# RESOLVER_RESOLVER_REGS_502CB000h register map
Vendor: Texas Instruments
Registers are 32-bit, read-write, reset 0x0 unless marked. A register's access mark holds for its fields unless they carry their own. Offsets are as the file gives them; [hi:lo] are bit positions; {n}, {i} and the like mark numbered series; 'fields as' and 'values as' point back to an identical list.

## RESOLVER_REGS (part 2 of 2)
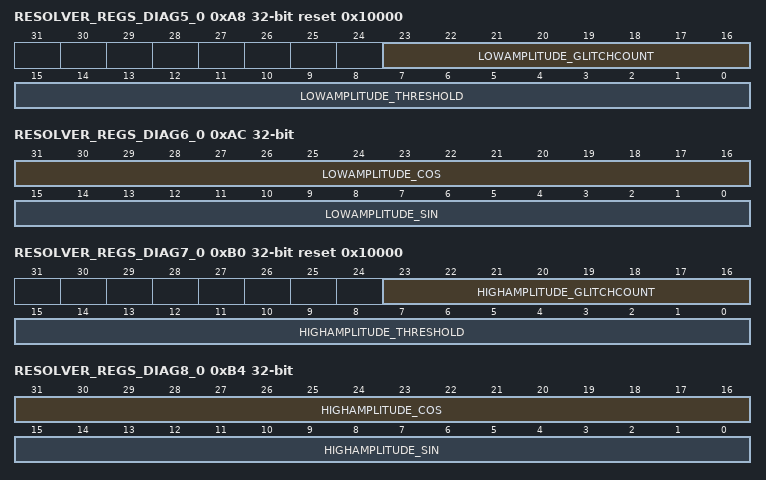
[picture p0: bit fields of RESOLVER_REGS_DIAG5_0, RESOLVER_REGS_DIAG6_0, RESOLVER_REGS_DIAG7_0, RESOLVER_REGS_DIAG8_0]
0xA8 RESOLVER_REGS_DIAG5_0 reset 0x10000 — Diag5 0
  [23:16] LOWAMPLITUDE_GLITCHCOUNT — Counter limit, how many times before issuing error
  [15:0] LOWAMPLITUDE_THRESHOLD — Hi threshold to detect lowamplitude. Both sin and cos need to be lower than this at the same time
0xAC RESOLVER_REGS_DIAG6_0 ro — Diag6 0
  [31:16] LOWAMPLITUDE_COS — Value of cos channel at the error trigger instant
  [15:0] LOWAMPLITUDE_SIN — Value of sin channel at the error trigger instant
0xB0 RESOLVER_REGS_DIAG7_0 reset 0x10000 — Diag7 0
  [23:16] HIGHAMPLITUDE_GLITCHCOUNT — Counter limit, how many times before issuing error
  [15:0] HIGHAMPLITUDE_THRESHOLD — Hi threshold to detect highamplitude. Both sin and cos need to be higher than this at the same time
0xB4 RESOLVER_REGS_DIAG8_0 ro — Diag8 0
  [31:16] HIGHAMPLITUDE_COS — Value of cos channel at the error trigger instant
  [15:0] HIGHAMPLITUDE_SIN — Value of sin channel at the error trigger instant
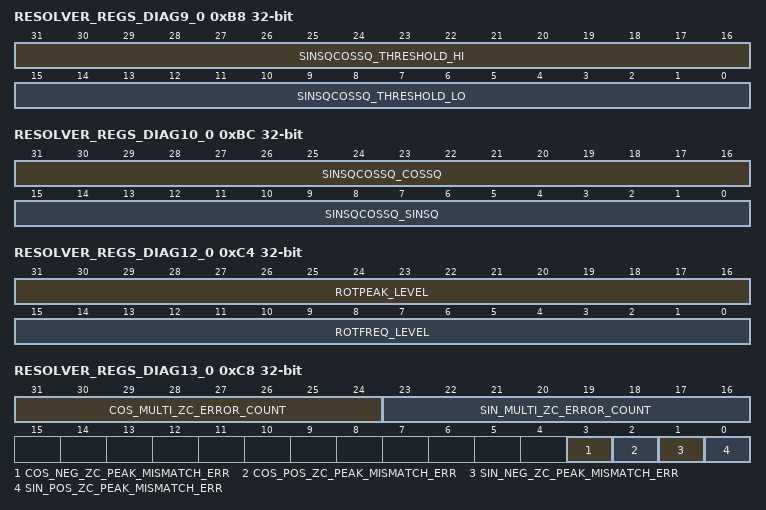
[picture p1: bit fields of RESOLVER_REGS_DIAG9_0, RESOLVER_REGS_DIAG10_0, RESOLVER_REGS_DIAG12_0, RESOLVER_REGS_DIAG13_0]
0xB8 RESOLVER_REGS_DIAG9_0 — Diag9 0
  [31:16] SINSQCOSSQ_THRESHOLD_HI — High threshold to detect sinsqcossq. Sin^2+Cos^2 s needs to be lower than this
  [15:0] SINSQCOSSQ_THRESHOLD_LO — Low threshold to detect sinsqcossq. Sin^2+Cos^2 s needs to be lower than this
0xBC RESOLVER_REGS_DIAG10_0 ro — Diag10 0
  [31:16] SINSQCOSSQ_COSSQ — Actual cossq value on error trigger ether lo or hi triggered, first event
  [15:0] SINSQCOSSQ_SINSQ — Actual sinsq value on error trigger ether lo or hi triggered, first event
0xC0 RESOLVER_REGS_DIAG11_0 reset 0x1 — Diag11 0
  [7:0] SINSQCOSSQ_GLITCHCOUNT — Counter limit, how many times before issuing error
0xC4 RESOLVER_REGS_DIAG12_0 — Diag12 0
  [31:16] ROTPEAK_LEVEL — Peak level of rotational sin/cos when other signal is zero crossing
  [15:0] ROTFREQ_LEVEL — Zero crossing detection level of rotational sin/cos
0xC8 RESOLVER_REGS_DIAG13_0 ro — Diag13 0
  [31:24] COS_MULTI_ZC_ERROR_COUNT — Status of cos Capture number of faulty zcs
  [23:16] SIN_MULTI_ZC_ERROR_COUNT — Status of sin Capture number of faulty zcs
  [3] COS_NEG_ZC_PEAK_MISMATCH_ERR — During negative cos zero-crossing cos is not + or - peak
  [2] COS_POS_ZC_PEAK_MISMATCH_ERR — During positive cos zero-croscosg cos is not + or - peak
  [1] SIN_NEG_ZC_PEAK_MISMATCH_ERR — During negative sin zero-crossing cos is not + or - peak
  [0] SIN_POS_ZC_PEAK_MISMATCH_ERR — During positive sin zero-crossing cos is not + or - peak
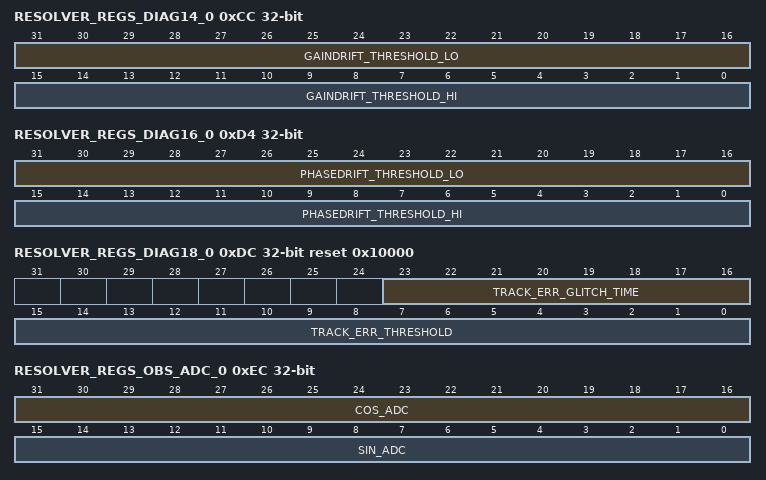
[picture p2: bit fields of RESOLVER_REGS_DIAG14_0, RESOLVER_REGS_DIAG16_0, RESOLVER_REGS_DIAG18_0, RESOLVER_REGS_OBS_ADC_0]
0xCC RESOLVER_REGS_DIAG14_0 — Diag14 0
  [31:16] GAINDRIFT_THRESHOLD_LO — Lo threshold to detect cos_gain drift
  [15:0] GAINDRIFT_THRESHOLD_HI — Hi threshold to detect cos_gain drift
0xD0 RESOLVER_REGS_DIAG15_0 reset 0x1 — Diag15 0
  [7:0] GAINDRIFT_GLITCHCOUNT — Counter limit, how many times before issuing error
0xD4 RESOLVER_REGS_DIAG16_0 — Diag16 0
  [31:16] PHASEDRIFT_THRESHOLD_LO — Lo threshold to detect cos phase drift
  [15:0] PHASEDRIFT_THRESHOLD_HI — Hi threshold to detect cos phase drift
0xD8 RESOLVER_REGS_DIAG17_0 reset 0x1 — Diag17 0
  [7:0] PHASEDRIFT_GLITCHCOUNT — Counter limit, how many times before issuing error
0xDC RESOLVER_REGS_DIAG18_0 reset 0x10000 — Diag18 0
  [23:16] TRACK_ERR_GLITCH_TIME — NOT USED
  [15:0] TRACK_ERR_THRESHOLD — Tracking error treshold
0xEC RESOLVER_REGS_OBS_ADC_0 ro — Sw Obs adc data post latch and avg if enabled
  [31:16] COS_ADC — Signed SW Obs adc data post latch and avg if enabled
  [15:0] SIN_ADC — Signed SW Obs adc data post latch and avg if enabled
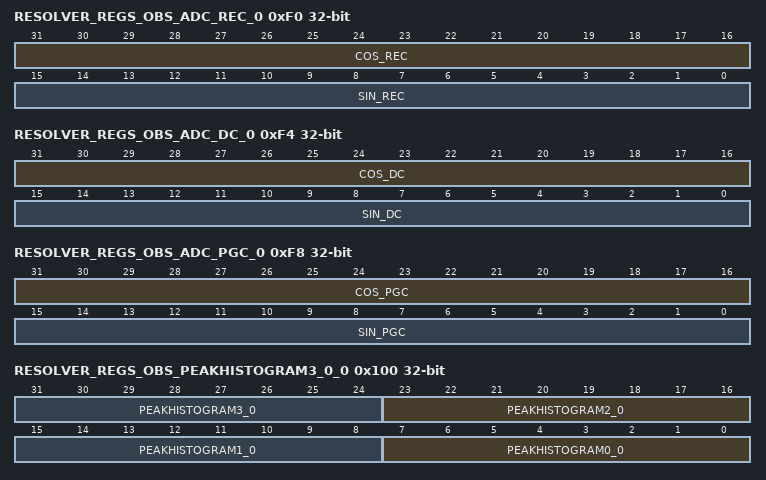
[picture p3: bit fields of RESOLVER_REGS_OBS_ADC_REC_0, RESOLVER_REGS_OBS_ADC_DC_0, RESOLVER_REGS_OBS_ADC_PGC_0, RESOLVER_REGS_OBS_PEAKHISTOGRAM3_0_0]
0xF0 RESOLVER_REGS_OBS_ADC_REC_0 ro — Sw Obs adc data post recovered data, so post dec
  [31:16] COS_REC — Signed SW Ob sadc data post recovered data, so post dec
  [15:0] SIN_REC — Signed SW Obs adc data post recovered data, so post dec
0xF4 RESOLVER_REGS_OBS_ADC_DC_0 ro — Sw Obs adc data post dc offset.
  [31:16] COS_DC — Signed SW Obs adc data post dc offset
  [15:0] SIN_DC — Signed SW Obs adc data post dc offset
0xF8 RESOLVER_REGS_OBS_ADC_PGC_0 ro — Sw Obs post phase and gain correction .
  [31:16] COS_PGC — Signed SW Obs adc data post phase and gain correction
  [15:0] SIN_PGC — Signed SW Obs adc data post phase and gain correction
0x100 RESOLVER_REGS_OBS_PEAKHISTOGRAM3_0_0 ro — SW obs peak histogram buckets.
  [8n+7:8n] PEAKHISTOGRAM{n}_0 (n=0..3) — Ideal sample bucket{n}
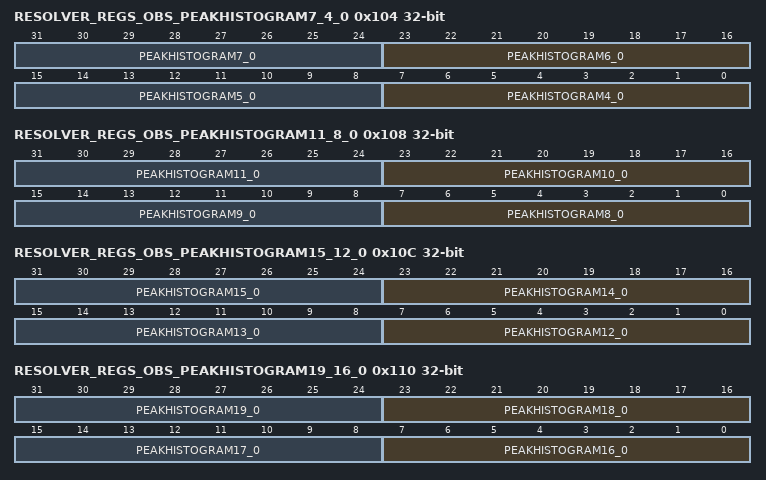
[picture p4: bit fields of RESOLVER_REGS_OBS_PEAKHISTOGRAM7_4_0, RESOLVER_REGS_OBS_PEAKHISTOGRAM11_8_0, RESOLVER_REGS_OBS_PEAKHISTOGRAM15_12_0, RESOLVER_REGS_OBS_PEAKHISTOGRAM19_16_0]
0x104 RESOLVER_REGS_OBS_PEAKHISTOGRAM7_4_0 ro — SW obs peak histogram buckets .
  [8n-25:8n-32] PEAKHISTOGRAM{n}_0 (n=4..7) — Ideal sample bucket{n}
0x108 RESOLVER_REGS_OBS_PEAKHISTOGRAM11_8_0 ro — SW obs peak histogram buckets .
  [8n-57:8n-64] PEAKHISTOGRAM{n}_0 (n=8..11) — Ideal sample bucket{n}
0x10C RESOLVER_REGS_OBS_PEAKHISTOGRAM15_12_0 ro — SW obs peak histogram buckets .
  [8n-89:8n-96] PEAKHISTOGRAM{n}_0 (n=12..15) — Ideal sample bucket{n}
0x110 RESOLVER_REGS_OBS_PEAKHISTOGRAM19_16_0 ro — SW obs peak histogram buckets .
  [8n-121:8n-128] PEAKHISTOGRAM{n}_0 (n=16..19) — Ideal sample bucket{n}
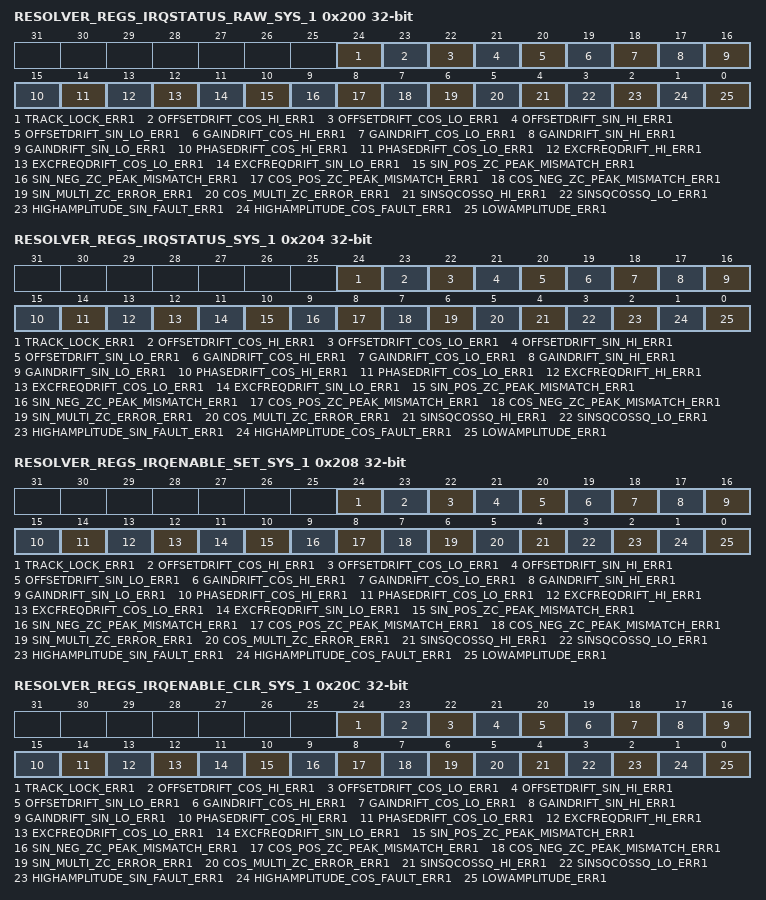
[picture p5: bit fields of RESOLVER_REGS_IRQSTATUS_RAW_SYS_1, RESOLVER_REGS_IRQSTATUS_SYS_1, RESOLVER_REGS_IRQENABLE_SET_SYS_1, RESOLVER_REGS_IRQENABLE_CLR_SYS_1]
0x200 RESOLVER_REGS_IRQSTATUS_RAW_SYS_1 access not given — Interrupt Raw Status Register for Core1.
  [24] TRACK_LOCK_ERR1 — Raw status of error interrupt for track_lock_err Write 1 to set the (raw) status, mostly for debug. Writing a 0 has no effect. (access R/W1TS)
  [23] OFFSETDRIFT_COS_HI_ERR1 — Raw status of error interrupt for offsetdrift_cos_hi_err Write 1 to set the (raw) status, mostly for debug. Writing a 0 has no effect. (access R/W1TS)
  [22] OFFSETDRIFT_COS_LO_ERR1 — Raw status of error interrupt for offsetdrift_cos_lo_err Write 1 to set the (raw) status, mostly for debug. Writing a 0 has no effect. (access R/W1TS)
  [21] OFFSETDRIFT_SIN_HI_ERR1 — Raw status of error interrupt for offsetdrift_sin_hi_err Write 1 to set the (raw) status, mostly for debug. Writing a 0 has no effect. (access R/W1TS)
  [20] OFFSETDRIFT_SIN_LO_ERR1 — Raw status of error interrupt for offsetdrift_sin_lo_err Write 1 to set the (raw) status, mostly for debug. Writing a 0 has no effect. (access R/W1TS)
  [19] GAINDRIFT_COS_HI_ERR1 — Raw status of error interrupt for gaindrift_cos_hi_err Write 1 to set the (raw) status, mostly for debug. Writing a 0 has no effect. (access R/W1TS)
  [18] GAINDRIFT_COS_LO_ERR1 — Raw status of error interrupt for gaindrift_cos_lo_err Write 1 to set the (raw) status, mostly for debug. Writing a 0 has no effect. (access R/W1TS)
  [17] GAINDRIFT_SIN_HI_ERR1 — Raw status of error interrupt for gaindrift_sin_hi_err Write 1 to set the (raw) status, mostly for debug. Writing a 0 has no effect. (access R/W1TS)
  [16] GAINDRIFT_SIN_LO_ERR1 — Raw status of error interrupt for gaindrift_sin_lo_err Write 1 to set the (raw) status, mostly for debug. Writing a 0 has no effect. (access R/W1TS)
  [15] PHASEDRIFT_COS_HI_ERR1 — Raw status of error interrupt for phasedrift_cos_hi_err Write 1 to set the (raw) status, mostly for debug. Writing a 0 has no effect. (access R/W1TS)
  [14] PHASEDRIFT_COS_LO_ERR1 — Raw status of error interrupt for phasedrift_cos_lo_err Write 1 to set the (raw) status, mostly for debug. Writing a 0 has no effect. (access R/W1TS)
  [13] EXCFREQDRIFT_HI_ERR1 — Raw status of error interrupt for excfreqdrift_hi_err Write 1 to set the (raw) status, mostly for debug. Writing a 0 has no effect. (access R/W1TS)
  [12] EXCFREQDRIFT_COS_LO_ERR1 — Raw status of error interrupt for excfreqdrift_cos_lo_err Write 1 to set the (raw) status, mostly for debug. Writing a 0 has no effect. (access R/W1TS)
  [11] EXCFREQDRIFT_SIN_LO_ERR1 — Raw status of error interrupt for excfreqdrift_sin_lo_err Write 1 to set the (raw) status, mostly for debug. Writing a 0 has no effect. (access R/W1TS)
  [10] SIN_POS_ZC_PEAK_MISMATCH_ERR1 — Raw status of error interrupt for sin_pos_zc_peak_mismatch_err Write 1 to set the (raw) status, mostly for debug. Writing a 0 has no effect. (access R/W1TS)
  [9] SIN_NEG_ZC_PEAK_MISMATCH_ERR1 — Raw status of error interrupt for sin_neg_zc_peak_mismatch_err Write 1 to set the (raw) status, mostly for debug. Writing a 0 has no effect. (access R/W1TS)
  [8] COS_POS_ZC_PEAK_MISMATCH_ERR1 — Raw status of error interrupt for cos_pos_zc_peak_mismatch_err Write 1 to set the (raw) status, mostly for debug. Writing a 0 has no effect. (access R/W1TS)
  [7] COS_NEG_ZC_PEAK_MISMATCH_ERR1 — Raw status of error interrupt for cos_neg_zc_peak_mismatch_err Write 1 to set the (raw) status, mostly for debug. Writing a 0 has no effect. (access R/W1TS)
  [6] SIN_MULTI_ZC_ERROR_ERR1 — Raw status of error interrupt for sin_multi_zc_error_err Write 1 to set the (raw) status, mostly for debug. Writing a 0 has no effect. (access R/W1TS)
  [5] COS_MULTI_ZC_ERROR_ERR1 — Raw status of error interrupt for cos_multi_zc_error_err Write 1 to set the (raw) status, mostly for debug. Writing a 0 has no effect. (access R/W1TS)
  [4] SINSQCOSSQ_HI_ERR1 — Raw status of error interrupt for sinsqcossq_hi_err Write 1 to set the (raw) status, mostly for debug. Writing a 0 has no effect. (access R/W1TS)
  [3] SINSQCOSSQ_LO_ERR1 — Raw status of error interrupt for sinsqcossq_lo_err Write 1 to set the (raw) status, mostly for debug. Writing a 0 has no effect. (access R/W1TS)
  [2] HIGHAMPLITUDE_SIN_FAULT_ERR1 — Raw status of error interrupt for highamplitude_sin_fault_err Write 1 to set the (raw) status, mostly for debug. Writing a 0 has no effect. (access R/W1TS)
  [1] HIGHAMPLITUDE_COS_FAULT_ERR1 — Raw status of error interrupt for highamplitude_cos_fault_err Write 1 to set the (raw) status, mostly for debug. Writing a 0 has no effect. (access R/W1TS)
  [0] LOWAMPLITUDE_ERR1 — Raw status of error interrupt for lowamplitude_err Write 1 to set the (raw) status, mostly for debug. Writing a 0 has no effect. (access R/W1TS)
0x204 RESOLVER_REGS_IRQSTATUS_SYS_1 access not given — Interrupt Status Register for Core1.
  [24] TRACK_LOCK_ERR1 — Enabled status of error interrupt for track_lock_err Write 1 to clear the status after interrupt has been serviced (raw status gets cleared, i.e. even if not enabled). Writing a 0 has no effect. (access R/W1TC)
  [23] OFFSETDRIFT_COS_HI_ERR1 — Enabled status of error interrupt for offsetdrift_cos_hi_err Write 1 to clear the status after interrupt has been serviced (raw status gets cleared, i.e. even if not enabled). Writing a 0 has no effect. (access R/W1TC)
  [22] OFFSETDRIFT_COS_LO_ERR1 — Enabled status of error interrupt for offsetdrift_cos_lo_err Write 1 to clear the status after interrupt has been serviced (raw status gets cleared, i.e. even if not enabled). Writing a 0 has no effect. (access R/W1TC)
  [21] OFFSETDRIFT_SIN_HI_ERR1 — Enabled status of error interrupt for offsetdrift_sin_hi_err Write 1 to clear the status after interrupt has been serviced (raw status gets cleared, i.e. even if not enabled). Writing a 0 has no effect. (access R/W1TC)
  [20] OFFSETDRIFT_SIN_LO_ERR1 — Enabled status of error interrupt for offsetdrift_sin_lo_err Write 1 to clear the status after interrupt has been serviced (raw status gets cleared, i.e. even if not enabled). Writing a 0 has no effect. (access R/W1TC)
  [19] GAINDRIFT_COS_HI_ERR1 — Enabled status of error interrupt for gaindrift_cos_hi_err Write 1 to clear the status after interrupt has been serviced (raw status gets cleared, i.e. even if not enabled). Writing a 0 has no effect. (access R/W1TC)
  [18] GAINDRIFT_COS_LO_ERR1 — Enabled status of error interrupt for gaindrift_cos_lo_err Write 1 to clear the status after interrupt has been serviced (raw status gets cleared, i.e. even if not enabled). Writing a 0 has no effect. (access R/W1TC)
  [17] GAINDRIFT_SIN_HI_ERR1 — Enabled status of error interrupt for gaindrift_sin_hi_err Write 1 to clear the status after interrupt has been serviced (raw status gets cleared, i.e. even if not enabled). Writing a 0 has no effect. (access R/W1TC)
  [16] GAINDRIFT_SIN_LO_ERR1 — Enabled status of error interrupt for gaindrift_sin_lo_err Write 1 to clear the status after interrupt has been serviced (raw status gets cleared, i.e. even if not enabled). Writing a 0 has no effect. (access R/W1TC)
  [15] PHASEDRIFT_COS_HI_ERR1 — Enabled status of error interrupt for phasedrift_cos_hi_err Write 1 to clear the status after interrupt has been serviced (raw status gets cleared, i.e. even if not enabled). Writing a 0 has no effect. (access R/W1TC)
  [14] PHASEDRIFT_COS_LO_ERR1 — Enabled status of error interrupt for phasedrift_cos_lo_err Write 1 to clear the status after interrupt has been serviced (raw status gets cleared, i.e. even if not enabled). Writing a 0 has no effect. (access R/W1TC)
  [13] EXCFREQDRIFT_HI_ERR1 — Enabled status of error interrupt for excfreqdrift_hi_err Write 1 to clear the status after interrupt has been serviced (raw status gets cleared, i.e. even if not enabled). Writing a 0 has no effect. (access R/W1TC)
  [12] EXCFREQDRIFT_COS_LO_ERR1 — Enabled status of error interrupt for excfreqdrift_cos_lo_err Write 1 to clear the status after interrupt has been serviced (raw status gets cleared, i.e. even if not enabled). Writing a 0 has no effect. (access R/W1TC)
  [11] EXCFREQDRIFT_SIN_LO_ERR1 — Enabled status of error interrupt for excfreqdrift_sin_lo_err Write 1 to clear the status after interrupt has been serviced (raw status gets cleared, i.e. even if not enabled). Writing a 0 has no effect. (access R/W1TC)
  [10] SIN_POS_ZC_PEAK_MISMATCH_ERR1 — Enabled status of error interrupt for sin_pos_zc_peak_mismatch_err Write 1 to clear the status after interrupt has been serviced (raw status gets cleared, i.e. even if not enabled). Writing a 0 has no effect. (access R/W1TC)
  [9] SIN_NEG_ZC_PEAK_MISMATCH_ERR1 — Enabled status of error interrupt for sin_neg_zc_peak_mismatch_err Write 1 to clear the status after interrupt has been serviced (raw status gets cleared, i.e. even if not enabled). Writing a 0 has no effect. (access R/W1TC)
  [8] COS_POS_ZC_PEAK_MISMATCH_ERR1 — Enabled status of error interrupt for cos_pos_zc_peak_mismatch_err Write 1 to clear the status after interrupt has been serviced (raw status gets cleared, i.e. even if not enabled). Writing a 0 has no effect. (access R/W1TC)
  [7] COS_NEG_ZC_PEAK_MISMATCH_ERR1 — Enabled status of error interrupt for cos_neg_zc_peak_mismatch_err Write 1 to clear the status after interrupt has been serviced (raw status gets cleared, i.e. even if not enabled). Writing a 0 has no effect. (access R/W1TC)
  [6] SIN_MULTI_ZC_ERROR_ERR1 — Enabled status of error interrupt for sin_multi_zc_error_err Write 1 to clear the status after interrupt has been serviced (raw status gets cleared, i.e. even if not enabled). Writing a 0 has no effect. (access R/W1TC)
  [5] COS_MULTI_ZC_ERROR_ERR1 — Enabled status of error interrupt for cos_multi_zc_error_err Write 1 to clear the status after interrupt has been serviced (raw status gets cleared, i.e. even if not enabled). Writing a 0 has no effect. (access R/W1TC)
  [4] SINSQCOSSQ_HI_ERR1 — Enabled status of error interrupt for sinsqcossq_hi_err Write 1 to clear the status after interrupt has been serviced (raw status gets cleared, i.e. even if not enabled). Writing a 0 has no effect. (access R/W1TC)
  [3] SINSQCOSSQ_LO_ERR1 — Enabled status of error interrupt for sinsqcossq_lo_err Write 1 to clear the status after interrupt has been serviced (raw status gets cleared, i.e. even if not enabled). Writing a 0 has no effect. (access R/W1TC)
  [2] HIGHAMPLITUDE_SIN_FAULT_ERR1 — Enabled status of error interrupt for highamplitude_sin_fault_err Write 1 to clear the status after interrupt has been serviced (raw status gets cleared, i.e. even if not enabled). Writing a 0 has no effect. (access R/W1TC)
  [1] HIGHAMPLITUDE_COS_FAULT_ERR1 — Enabled status of error interrupt for highamplitude_cos_fault_err Write 1 to clear the status after interrupt has been serviced (raw status gets cleared, i.e. even if not enabled). Writing a 0 has no effect. (access R/W1TC)
  [0] LOWAMPLITUDE_ERR1 — Enabled status of error interrupt for lowamplitude_err Write 1 to clear the status after interrupt has been serviced (raw status gets cleared, i.e. even if not enabled). Writing a 0 has no effect. (access R/W1TC)
0x208 RESOLVER_REGS_IRQENABLE_SET_SYS_1 access not given — Interrupt Enable Set Register for Core1.
  [24] TRACK_LOCK_ERR1 — Enable set for track_lock_err . Writing a 1 will enable the interrupt, and set this bit as well as the corresponding Interrupt Enable Clear Register. Writing a 0 has no effect. (access R/W1TS)
  [23] OFFSETDRIFT_COS_HI_ERR1 — Enable set for offsetdrift_cos_hi_err . Writing a 1 will enable the interrupt, and set this bit as well as the corresponding Interrupt Enable Clear Register. Writing a 0 has no effect. (access R/W1TS)
  [22] OFFSETDRIFT_COS_LO_ERR1 — Enable set for offsetdrift_cos_lo_err . Writing a 1 will enable the interrupt, and set this bit as well as the corresponding Interrupt Enable Clear Register. Writing a 0 has no effect. (access R/W1TS)
  [21] OFFSETDRIFT_SIN_HI_ERR1 — Enable set for offsetdrift_sin_hi_err . Writing a 1 will enable the interrupt, and set this bit as well as the corresponding Interrupt Enable Clear Register. Writing a 0 has no effect. (access R/W1TS)
  [20] OFFSETDRIFT_SIN_LO_ERR1 — Enable set for offsetdrift_sin_lo_err . Writing a 1 will enable the interrupt, and set this bit as well as the corresponding Interrupt Enable Clear Register. Writing a 0 has no effect. (access R/W1TS)
  [19] GAINDRIFT_COS_HI_ERR1 — Enable set for gaindrift_cos_hi_err . Writing a 1 will enable the interrupt, and set this bit as well as the corresponding Interrupt Enable Clear Register. Writing a 0 has no effect. (access R/W1TS)
  [18] GAINDRIFT_COS_LO_ERR1 — Enable set for gaindrift_cos_lo_err . Writing a 1 will enable the interrupt, and set this bit as well as the corresponding Interrupt Enable Clear Register. Writing a 0 has no effect. (access R/W1TS)
  [17] GAINDRIFT_SIN_HI_ERR1 — Enable set for gaindrift_sin_hi_err . Writing a 1 will enable the interrupt, and set this bit as well as the corresponding Interrupt Enable Clear Register. Writing a 0 has no effect. (access R/W1TS)
  [16] GAINDRIFT_SIN_LO_ERR1 — Enable set for gaindrift_sin_lo_err . Writing a 1 will enable the interrupt, and set this bit as well as the corresponding Interrupt Enable Clear Register. Writing a 0 has no effect. (access R/W1TS)
  [15] PHASEDRIFT_COS_HI_ERR1 — Enable set for phasedrift_cos_hi_err . Writing a 1 will enable the interrupt, and set this bit as well as the corresponding Interrupt Enable Clear Register. Writing a 0 has no effect. (access R/W1TS)
  [14] PHASEDRIFT_COS_LO_ERR1 — Enable set for phasedrift_cos_lo_err . Writing a 1 will enable the interrupt, and set this bit as well as the corresponding Interrupt Enable Clear Register. Writing a 0 has no effect. (access R/W1TS)
  [13] EXCFREQDRIFT_HI_ERR1 — Enable set for excfreqdrift_hi_err . Writing a 1 will enable the interrupt, and set this bit as well as the corresponding Interrupt Enable Clear Register. Writing a 0 has no effect. (access R/W1TS)
  [12] EXCFREQDRIFT_COS_LO_ERR1 — Enable set for excfreqdrift_cos_lo_err . Writing a 1 will enable the interrupt, and set this bit as well as the corresponding Interrupt Enable Clear Register. Writing a 0 has no effect. (access R/W1TS)
  [11] EXCFREQDRIFT_SIN_LO_ERR1 — Enable set for excfreqdrift_sin_lo_err . Writing a 1 will enable the interrupt, and set this bit as well as the corresponding Interrupt Enable Clear Register. Writing a 0 has no effect. (access R/W1TS)
  [10] SIN_POS_ZC_PEAK_MISMATCH_ERR1 — Enable set for sin_pos_zc_peak_mismatch_err . Writing a 1 will enable the interrupt, and set this bit as well as the corresponding Interrupt Enable Clear Register. Writing a 0 has no effect. (access R/W1TS)
  [9] SIN_NEG_ZC_PEAK_MISMATCH_ERR1 — Enable set for sin_neg_zc_peak_mismatch_err . Writing a 1 will enable the interrupt, and set this bit as well as the corresponding Interrupt Enable Clear Register. Writing a 0 has no effect. (access R/W1TS)
  [8] COS_POS_ZC_PEAK_MISMATCH_ERR1 — Enable set for cos_pos_zc_peak_mismatch_err . Writing a 1 will enable the interrupt, and set this bit as well as the corresponding Interrupt Enable Clear Register. Writing a 0 has no effect. (access R/W1TS)
  [7] COS_NEG_ZC_PEAK_MISMATCH_ERR1 — Enable set for cos_neg_zc_peak_mismatch_err . Writing a 1 will enable the interrupt, and set this bit as well as the corresponding Interrupt Enable Clear Register. Writing a 0 has no effect. (access R/W1TS)
  [6] SIN_MULTI_ZC_ERROR_ERR1 — Enable set for sin_multi_zc_error_err . Writing a 1 will enable the interrupt, and set this bit as well as the corresponding Interrupt Enable Clear Register. Writing a 0 has no effect. (access R/W1TS)
  [5] COS_MULTI_ZC_ERROR_ERR1 — Enable set for cos_multi_zc_error_err . Writing a 1 will enable the interrupt, and set this bit as well as the corresponding Interrupt Enable Clear Register. Writing a 0 has no effect. (access R/W1TS)
  [4] SINSQCOSSQ_HI_ERR1 — Enable set for sinsqcossq_hi_err . Writing a 1 will enable the interrupt, and set this bit as well as the corresponding Interrupt Enable Clear Register. Writing a 0 has no effect. (access R/W1TS)
  [3] SINSQCOSSQ_LO_ERR1 — Enable set for sinsqcossq_lo_err . Writing a 1 will enable the interrupt, and set this bit as well as the corresponding Interrupt Enable Clear Register. Writing a 0 has no effect. (access R/W1TS)
  [2] HIGHAMPLITUDE_SIN_FAULT_ERR1 — Enable set for highamplitude_sin_fault_err . Writing a 1 will enable the interrupt, and set this bit as well as the corresponding Interrupt Enable Clear Register. Writing a 0 has no effect. (access R/W1TS)
  [1] HIGHAMPLITUDE_COS_FAULT_ERR1 — Enable set for highamplitude_cos_fault_err . Writing a 1 will enable the interrupt, and set this bit as well as the corresponding Interrupt Enable Clear Register. Writing a 0 has no effect. (access R/W1TS)
  [0] LOWAMPLITUDE_ERR1 — Enable set for lowamplitude_err . Writing a 1 will enable the interrupt, and set this bit as well as the corresponding Interrupt Enable Clear Register. Writing a 0 has no effect. (access R/W1TS)
0x20C RESOLVER_REGS_IRQENABLE_CLR_SYS_1 access not given — Interrupt Enable Clear Register for Core1.
  [24] TRACK_LOCK_ERR1 — Enable clr for track_lock_err. Writing a 1 will disable the interrupt, and set this bit as well as the corresponding Interrupt Enable set Register. Writing a 0 has no effect. (access R/W1TS)
  [23] OFFSETDRIFT_COS_HI_ERR1 — Enable clr for offsetdrift_cos_hi_err. Writing a 1 will disable the interrupt, and set this bit as well as the corresponding Interrupt Enable set Register. Writing a 0 has no effect. (access R/W1TS)
  [22] OFFSETDRIFT_COS_LO_ERR1 — Enable clr for offsetdrift_cos_lo_err. Writing a 1 will disable the interrupt, and set this bit as well as the corresponding Interrupt Enable set Register. Writing a 0 has no effect. (access R/W1TS)
  [21] OFFSETDRIFT_SIN_HI_ERR1 — Enable clr for offsetdrift_sin_hi_err. Writing a 1 will disable the interrupt, and set this bit as well as the corresponding Interrupt Enable set Register. Writing a 0 has no effect. (access R/W1TS)
  [20] OFFSETDRIFT_SIN_LO_ERR1 — Enable clr for offsetdrift_sin_lo_err. Writing a 1 will disable the interrupt, and set this bit as well as the corresponding Interrupt Enable set Register. Writing a 0 has no effect. (access R/W1TS)
  [19] GAINDRIFT_COS_HI_ERR1 — Enable clr for gaindrift_cos_hi_err. Writing a 1 will disable the interrupt, and set this bit as well as the corresponding Interrupt Enable set Register. Writing a 0 has no effect. (access R/W1TS)
  [18] GAINDRIFT_COS_LO_ERR1 — Enable clr for gaindrift_cos_lo_err. Writing a 1 will disable the interrupt, and set this bit as well as the corresponding Interrupt Enable set Register. Writing a 0 has no effect. (access R/W1TS)
  [17] GAINDRIFT_SIN_HI_ERR1 — Enable clr for gaindrift_sin_hi_err. Writing a 1 will disable the interrupt, and set this bit as well as the corresponding Interrupt Enable set Register. Writing a 0 has no effect. (access R/W1TS)
  [16] GAINDRIFT_SIN_LO_ERR1 — Enable clr for gaindrift_sin_lo_err. Writing a 1 will disable the interrupt, and set this bit as well as the corresponding Interrupt Enable set Register. Writing a 0 has no effect. (access R/W1TS)
  [15] PHASEDRIFT_COS_HI_ERR1 — Enable clr for phasedrift_cos_hi_err. Writing a 1 will disable the interrupt, and set this bit as well as the corresponding Interrupt Enable set Register. Writing a 0 has no effect. (access R/W1TS)
  [14] PHASEDRIFT_COS_LO_ERR1 — Enable clr for phasedrift_cos_lo_err. Writing a 1 will disable the interrupt, and set this bit as well as the corresponding Interrupt Enable set Register. Writing a 0 has no effect. (access R/W1TS)
  [13] EXCFREQDRIFT_HI_ERR1 — Enable clr for excfreqdrift_hi_err. Writing a 1 will disable the interrupt, and set this bit as well as the corresponding Interrupt Enable set Register. Writing a 0 has no effect. (access R/W1TS)
  [12] EXCFREQDRIFT_COS_LO_ERR1 — Enable clr for excfreqdrift_cos_lo_err. Writing a 1 will disable the interrupt, and set this bit as well as the corresponding Interrupt Enable set Register. Writing a 0 has no effect. (access R/W1TS)
  [11] EXCFREQDRIFT_SIN_LO_ERR1 — Enable clr for excfreqdrift_sin_lo_err. Writing a 1 will disable the interrupt, and set this bit as well as the corresponding Interrupt Enable set Register. Writing a 0 has no effect. (access R/W1TS)
  [10] SIN_POS_ZC_PEAK_MISMATCH_ERR1 — Enable clr for sin_pos_zc_peak_mismatch_err. Writing a 1 will disable the interrupt, and set this bit as well as the corresponding Interrupt Enable set Register. Writing a 0 has no effect. (access R/W1TS)
  [9] SIN_NEG_ZC_PEAK_MISMATCH_ERR1 — Enable clr for sin_neg_zc_peak_mismatch_err. Writing a 1 will disable the interrupt, and set this bit as well as the corresponding Interrupt Enable set Register. Writing a 0 has no effect. (access R/W1TS)
  [8] COS_POS_ZC_PEAK_MISMATCH_ERR1 — Enable clr for cos_pos_zc_peak_mismatch_err. Writing a 1 will disable the interrupt, and set this bit as well as the corresponding Interrupt Enable set Register. Writing a 0 has no effect. (access R/W1TS)
  [7] COS_NEG_ZC_PEAK_MISMATCH_ERR1 — Enable clr for cos_neg_zc_peak_mismatch_err. Writing a 1 will disable the interrupt, and set this bit as well as the corresponding Interrupt Enable set Register. Writing a 0 has no effect. (access R/W1TS)
  [6] SIN_MULTI_ZC_ERROR_ERR1 — Enable clr for sin_multi_zc_error_err. Writing a 1 will disable the interrupt, and set this bit as well as the corresponding Interrupt Enable set Register. Writing a 0 has no effect. (access R/W1TS)
  [5] COS_MULTI_ZC_ERROR_ERR1 — Enable clr for cos_multi_zc_error_err. Writing a 1 will disable the interrupt, and set this bit as well as the corresponding Interrupt Enable set Register. Writing a 0 has no effect. (access R/W1TS)
  [4] SINSQCOSSQ_HI_ERR1 — Enable clr for sinsqcossq_hi_err. Writing a 1 will disable the interrupt, and set this bit as well as the corresponding Interrupt Enable set Register. Writing a 0 has no effect. (access R/W1TS)
  [3] SINSQCOSSQ_LO_ERR1 — Enable clr for sinsqcossq_lo_err. Writing a 1 will disable the interrupt, and set this bit as well as the corresponding Interrupt Enable set Register. Writing a 0 has no effect. (access R/W1TS)
  [2] HIGHAMPLITUDE_SIN_FAULT_ERR1 — Enable clr for highamplitude_sin_fault_err. Writing a 1 will disable the interrupt, and set this bit as well as the corresponding Interrupt Enable set Register. Writing a 0 has no effect. (access R/W1TS)
  [1] HIGHAMPLITUDE_COS_FAULT_ERR1 — Enable clr for highamplitude_cos_fault_err. Writing a 1 will disable the interrupt, and set this bit as well as the corresponding Interrupt Enable set Register. Writing a 0 has no effect. (access R/W1TS)
  [0] LOWAMPLITUDE_ERR1 — Enable clr for lowamplitude_err. Writing a 1 will disable the interrupt, and set this bit as well as the corresponding Interrupt Enable set Register. Writing a 0 has no effect. (access R/W1TS)
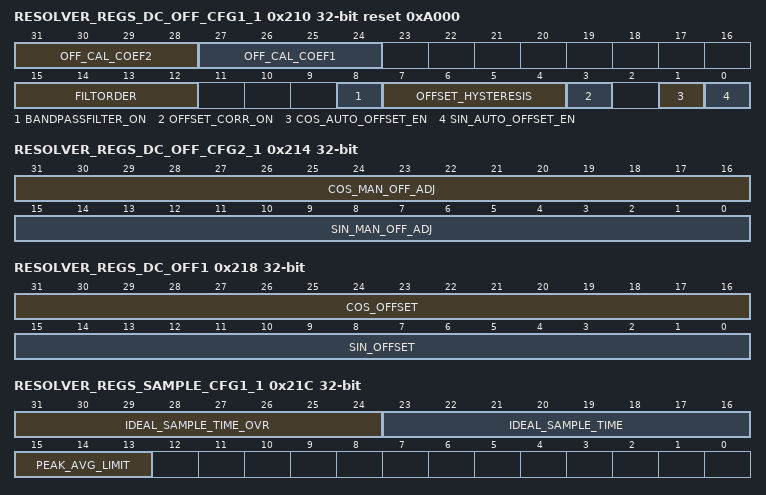
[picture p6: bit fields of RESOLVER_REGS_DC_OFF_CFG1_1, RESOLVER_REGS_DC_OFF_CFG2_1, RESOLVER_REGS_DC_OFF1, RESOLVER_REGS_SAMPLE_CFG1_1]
0x210 RESOLVER_REGS_DC_OFF_CFG1_1 reset 0xA000 — DC Offset Config1.
  [31:28] OFF_CAL_COEF2 — Offset calibration coefficient2 dc offset
  [27:24] OFF_CAL_COEF1 — Offset calibration coefficient1 dc offset
  [15:12] FILTORDER — NOT USED
  [8] BANDPASSFILTER_ON — To enable the bandpass filter before DC offset logix
  [7:4] OFFSET_HYSTERESIS — unsigned. Absolute hysteresis limit.4b(no decimal points) with the16bLSB, ADC data coming16bto the resolver
  [3] OFFSET_CORR_ON — DC Offset Correction On
  [1] COS_AUTO_OFFSET_EN — NOT_USED
  [0] SIN_AUTO_OFFSET_EN — NOT USED
0x214 RESOLVER_REGS_DC_OFF_CFG2_1 — DC Offset Config2.
  [31:16] COS_MAN_OFF_ADJ — Signed Cos manual dc offset
  [15:0] SIN_MAN_OFF_ADJ — Signed Sin manual dc offset
0x218 RESOLVER_REGS_DC_OFF1 ro — DC Offset.
  [31:16] COS_OFFSET — Signed Cos auto dc offset
  [15:0] SIN_OFFSET — Signed Sin auto dc offset
0x21C RESOLVER_REGS_SAMPLE_CFG1_1 access per field — Ideal Sample Config1.
  [31:24] IDEAL_SAMPLE_TIME_OVR rw — Ideal sample count Overide
  [23:16] IDEAL_SAMPLE_TIME ro — Current Ideal sample count, round down
  [15:13] PEAK_AVG_LIMIT rw — 2^n peakaveragelimit is how many times to average the ideal peak point: 0 to 7
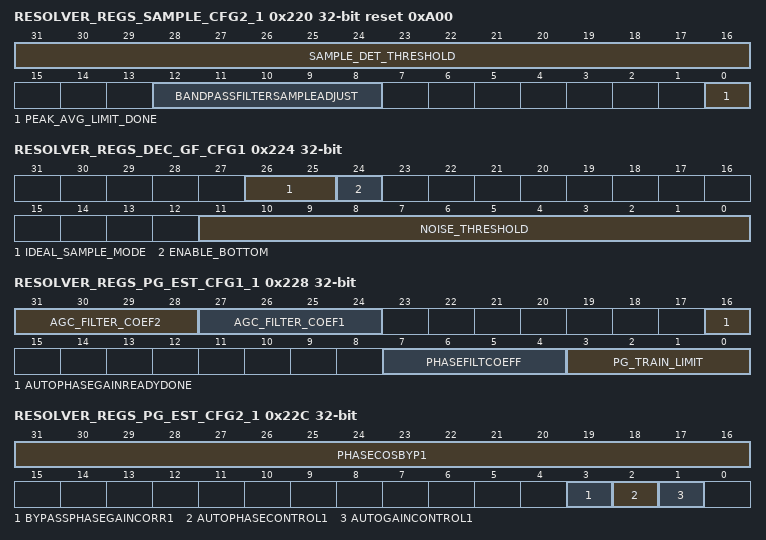
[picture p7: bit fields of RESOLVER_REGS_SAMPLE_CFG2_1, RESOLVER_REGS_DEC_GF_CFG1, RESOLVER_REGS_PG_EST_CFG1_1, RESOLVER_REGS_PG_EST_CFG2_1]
0x220 RESOLVER_REGS_SAMPLE_CFG2_1 access not given reset 0xA00 — Ideal Sample Config2.
  [31:16] SAMPLE_DET_THRESHOLD rw — Abs value, the sig needs to be above to trigger the peak detect
  [12:8] BANDPASSFILTERSAMPLEADJUST rw — Offset compensate the ideal phase time selection if bpass filter enabled note when you are in manual mode, this value is not longer added
  [0] PEAK_AVG_LIMIT_DONE — Ideal sample count training completed, Wrt 1 to Clr (access R/W1TC)
0x224 RESOLVER_REGS_DEC_GF_CFG1 — Dec GF Config.
  [26:25] IDEAL_SAMPLE_MODE — Ideal sample time detection: 0 autodetect, 1 detect on sin channel 2 on cos channel 3 manual
  [24] ENABLE_BOTTOM — This enables bottom wave to get used in the avg
  [11:0] NOISE_THRESHOLD — Abs value, if above use the current moving avg, drop the new data
0x228 RESOLVER_REGS_PG_EST_CFG1_1 access not given — Phase and Gain Est for correction block Config1.
  [31:28] AGC_FILTER_COEF2 rw — NOT USED
  [27:24] AGC_FILTER_COEF1 rw — NOT USED
  [16] AUTOPHASEGAINREADYDONE — Status of Auto Gain and Phase Est , set when ready for each cycle , wrt 1 to clear, this has no effect to the correction logic (access R/W1TC)
  [7:4] PHASEFILTCOEFF rw — NOT USED
  [3:0] PG_TRAIN_LIMIT rw — ^n pg_train_limit : 0 to 15
0x22C RESOLVER_REGS_PG_EST_CFG2_1 — Phase and Gain Est for correction block Config2.
  [31:16] PHASECOSBYP1 — Manual Phase Cos correction value
  [3] BYPASSPHASEGAINCORR1 — Enables phase and gain est
  [2] AUTOPHASECONTROL1 — Enable Auto Phase correction
  [1] AUTOGAINCONTROL1 — Enable Auto Gain correction
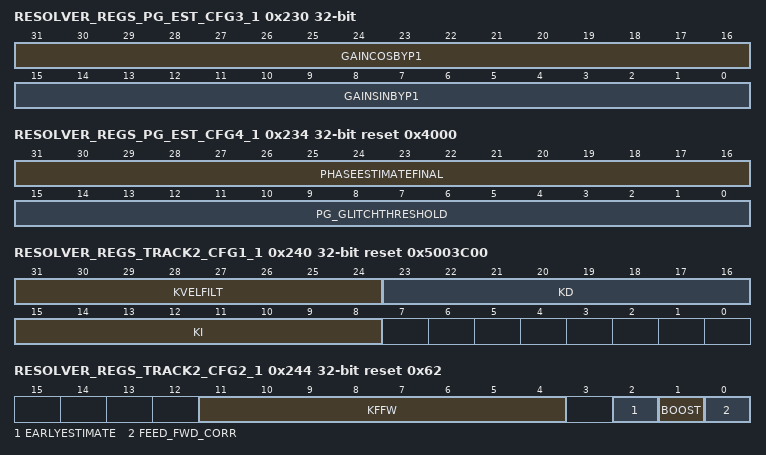
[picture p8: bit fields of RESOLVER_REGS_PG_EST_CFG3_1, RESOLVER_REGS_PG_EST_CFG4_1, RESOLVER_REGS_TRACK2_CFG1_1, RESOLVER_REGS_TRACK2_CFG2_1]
0x230 RESOLVER_REGS_PG_EST_CFG3_1 — Phase and Gain Est for correction block Config3.
  [31:16] GAINCOSBYP1 — Manual Gain Cos correction value
  [15:0] GAINSINBYP1 — Manual Gain Sin correction value, always pos
0x234 RESOLVER_REGS_PG_EST_CFG4_1 access per field reset 0x4000 — Phase and Gain Est for correction block Config4.
  [31:16] PHASEESTIMATEFINAL ro — Cos Auto Cal Phase correction value cal by est
  [15:0] PG_GLITCHTHRESHOLD rw — glitch threshold to estimate new rotation start in degrees
0x238 RESOLVER_REGS_PG_EST_CFG5_1 ro — Phase and Gain Est for correction block Config5.
  [31:0] COSSQACCFINAL1 — Cos Auto Cal Gain correction value cal by est
0x23C RESOLVER_REGS_PG_EST_CFG6_1 ro — Phase and Gain Est for correction block Config6.
  [31:0] SINSQACCFINAL1 — Sin Auto Cal Gain correction value cal by est
0x240 RESOLVER_REGS_TRACK2_CFG1_1 reset 0x5003C00 — Track2 Kp, Ki, Kd, Kvelfilt, Kffw, Boost Cfg1 .
  [31:24] KVELFILT
  [23:16] KD — NOT USED
  [15:8] KI
0x244 RESOLVER_REGS_TRACK2_CFG2_1 reset 0x62 — Track2 Feed Fwd Boost Kffw Cfg2.
  [11:4] KFFW
  [2] EARLYESTIMATE — NOT USED
  [1] BOOST — Boost Enable
  [0] FEED_FWD_CORR — NOT USED
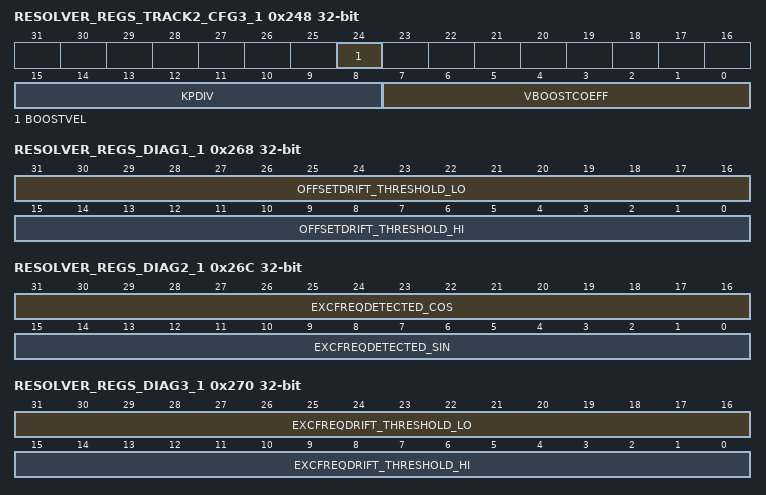
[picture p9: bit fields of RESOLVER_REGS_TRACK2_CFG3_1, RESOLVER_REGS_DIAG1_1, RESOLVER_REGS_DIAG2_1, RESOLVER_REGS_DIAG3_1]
0x248 RESOLVER_REGS_TRACK2_CFG3_1 — Track2 Cfg3.
  [24] BOOSTVEL — 0 disables and 1 enables accel/decel compensation for velocity calculation. boost also needs to be 1
  [15:8] KPDIV — Kp proportional path gain
  [7:0] VBOOSTCOEFF — unsigned velocity accel/decel comp coefficient
0x24C RESOLVER_REGS_ANGLE_ARCTAN_1 ro — Angle and Velocity from acrtan .
  [15:0] ANGLE — Signed(2s complement) Angle from arctan -180 to 0 to +180 scaled
0x250 RESOLVER_REGS_ANGLE_TRACK2_1 ro — Angle and Velocity from track2.
  [15:0] ANGLE — Signed(2s complement) Angle from track2 -180 to 0 to +180 scaled
0x254 RESOLVER_REGS_VELOCITY_TRACK2_1 ro — Angle and Velocity from track2.
  [31:0] VELOCITY — This register gives rotation frequency as a function of exc freq and double/single sample mode. Formula on matlab comment. (rotation frequency in Hz, signed based on direction) = (velocity) * (1/Ts) * 1/2^32 Note: if it's top/bottom sampling, Ts = Texc/2, otherwise Ts=Texc
0x258 RESOLVER_REGS_OFFSET_1 access not given reset not defined — SIN and COS Offset.
0x268 RESOLVER_REGS_DIAG1_1 — Diag1 1
  [31:16] OFFSETDRIFT_THRESHOLD_LO — Signed Lo threshold to detect offset drift
  [15:0] OFFSETDRIFT_THRESHOLD_HI — Signed Hi threshold to detect offsetdrift
0x26C RESOLVER_REGS_DIAG2_1 ro — Diag2 1
  [31:16] EXCFREQDETECTED_COS — SW OBS Counts detected between zcs for cos excitation frequency
  [15:0] EXCFREQDETECTED_SIN — SW OBS Counts detected between zcs for sin excitation frequency
0x270 RESOLVER_REGS_DIAG3_1 — Diag3 1
  [31:16] EXCFREQDRIFT_THRESHOLD_LO — Lo threshold to detect excfreqdrift
  [15:0] EXCFREQDRIFT_THRESHOLD_HI — Hi threshold to detect excfreqdrift
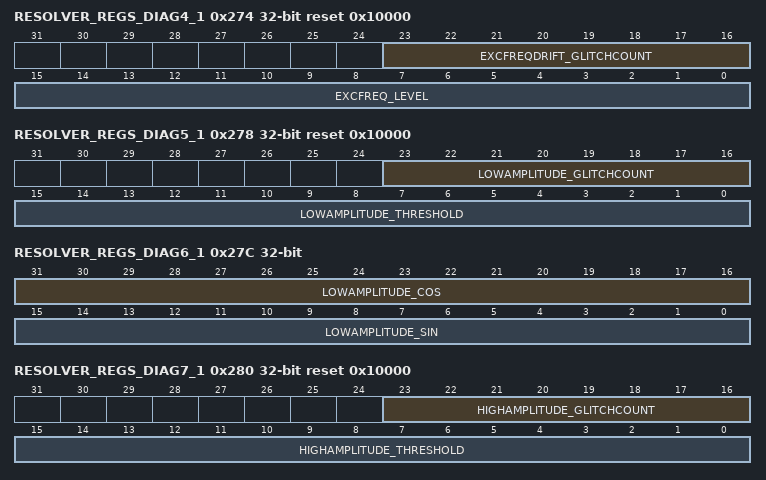
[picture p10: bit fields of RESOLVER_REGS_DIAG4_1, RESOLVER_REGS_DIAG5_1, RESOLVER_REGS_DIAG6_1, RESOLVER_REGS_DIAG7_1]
0x274 RESOLVER_REGS_DIAG4_1 reset 0x10000 — Diag4 1
  [23:16] EXCFREQDRIFT_GLITCHCOUNT — Counter limit, how many times before issuing error
  [15:0] EXCFREQ_LEVEL — Threshold on ADC value to detect sin or cos zero crossings
0x278 RESOLVER_REGS_DIAG5_1 reset 0x10000 — Diag5 1
  fields as RESOLVER_REGS_DIAG5_0
0x27C RESOLVER_REGS_DIAG6_1 ro — Diag6 1
  fields as RESOLVER_REGS_DIAG6_0
0x280 RESOLVER_REGS_DIAG7_1 reset 0x10000 — Diag7 1
  fields as RESOLVER_REGS_DIAG7_0
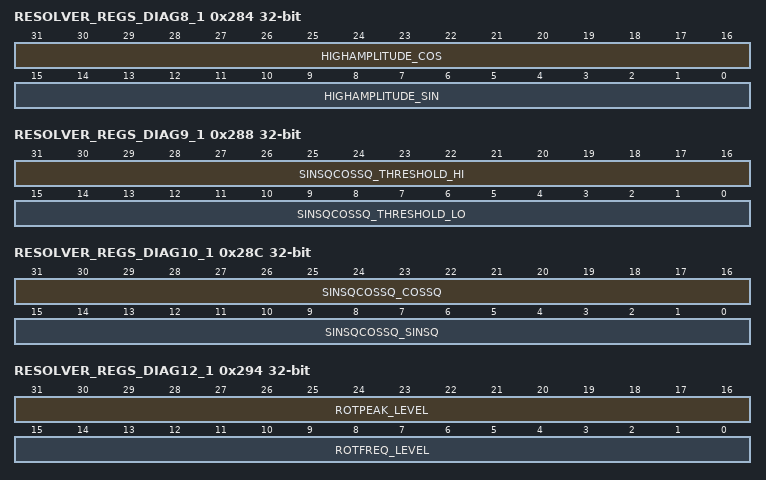
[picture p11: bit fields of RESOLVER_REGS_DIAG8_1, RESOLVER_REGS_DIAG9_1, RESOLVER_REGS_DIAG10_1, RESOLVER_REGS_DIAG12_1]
0x284 RESOLVER_REGS_DIAG8_1 ro — Diag8 1
  fields as RESOLVER_REGS_DIAG8_0
0x288 RESOLVER_REGS_DIAG9_1 — Diag9 1
  fields as RESOLVER_REGS_DIAG9_0
0x28C RESOLVER_REGS_DIAG10_1 ro — Diag10 1
  fields as RESOLVER_REGS_DIAG10_0
0x290 RESOLVER_REGS_DIAG11_1 reset 0x1 — Diag11 1
  fields as RESOLVER_REGS_DIAG11_0
0x294 RESOLVER_REGS_DIAG12_1 — Diag12 1
  fields as RESOLVER_REGS_DIAG12_0
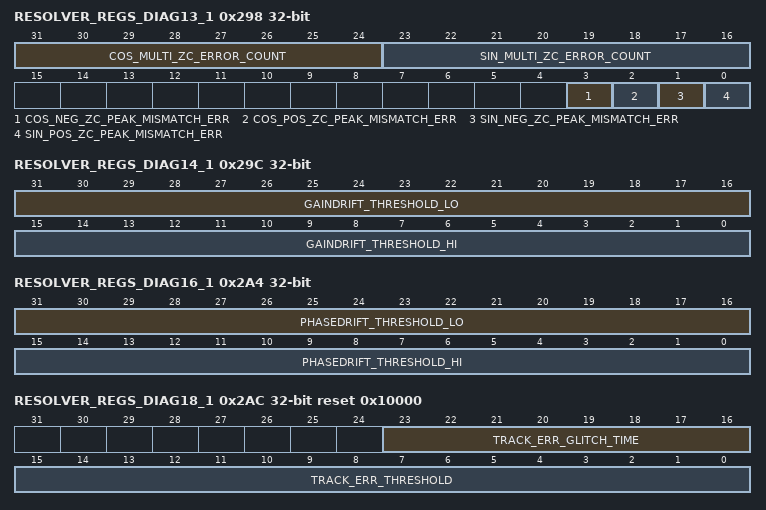
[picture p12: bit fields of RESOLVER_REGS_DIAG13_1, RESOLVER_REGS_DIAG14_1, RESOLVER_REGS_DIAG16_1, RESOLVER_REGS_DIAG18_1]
0x298 RESOLVER_REGS_DIAG13_1 ro — Diag13 1
  fields as RESOLVER_REGS_DIAG13_0
0x29C RESOLVER_REGS_DIAG14_1 — Diag14 1
  fields as RESOLVER_REGS_DIAG14_0
0x2A0 RESOLVER_REGS_DIAG15_1 reset 0x1 — Diag15 1
  fields as RESOLVER_REGS_DIAG15_0
0x2A4 RESOLVER_REGS_DIAG16_1 — Diag16 1
  fields as RESOLVER_REGS_DIAG16_0
0x2A8 RESOLVER_REGS_DIAG17_1 reset 0x1 — Diag17 1
  fields as RESOLVER_REGS_DIAG17_0
0x2AC RESOLVER_REGS_DIAG18_1 reset 0x10000 — Diag18 1
  fields as RESOLVER_REGS_DIAG18_0
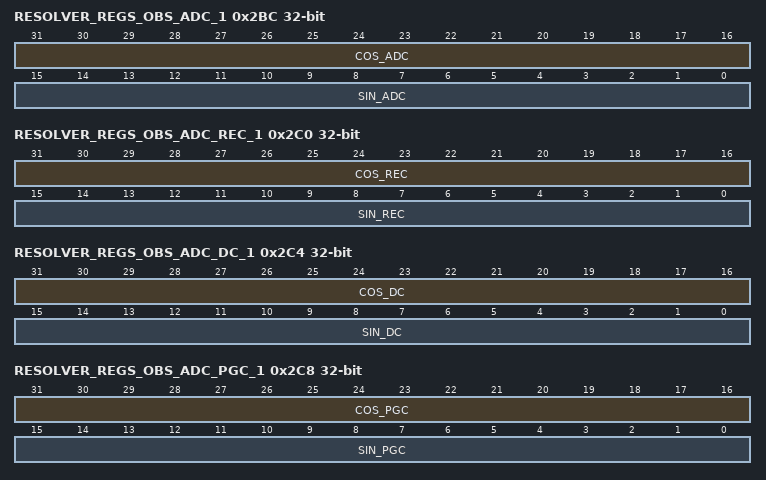
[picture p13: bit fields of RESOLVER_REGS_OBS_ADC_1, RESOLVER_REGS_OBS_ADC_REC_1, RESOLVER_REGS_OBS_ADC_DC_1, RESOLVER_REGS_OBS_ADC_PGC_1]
0x2BC RESOLVER_REGS_OBS_ADC_1 ro — Sw Obs adc data post latch and avg if enabled
  fields as RESOLVER_REGS_OBS_ADC_0
0x2C0 RESOLVER_REGS_OBS_ADC_REC_1 ro — Sw Obs adc data post recovered data, so post dec
  fields as RESOLVER_REGS_OBS_ADC_REC_0
0x2C4 RESOLVER_REGS_OBS_ADC_DC_1 ro — Sw Obs adc data post dc offset.
  fields as RESOLVER_REGS_OBS_ADC_DC_0
0x2C8 RESOLVER_REGS_OBS_ADC_PGC_1 ro — Sw Obs post phase and gain correction .
  fields as RESOLVER_REGS_OBS_ADC_PGC_0
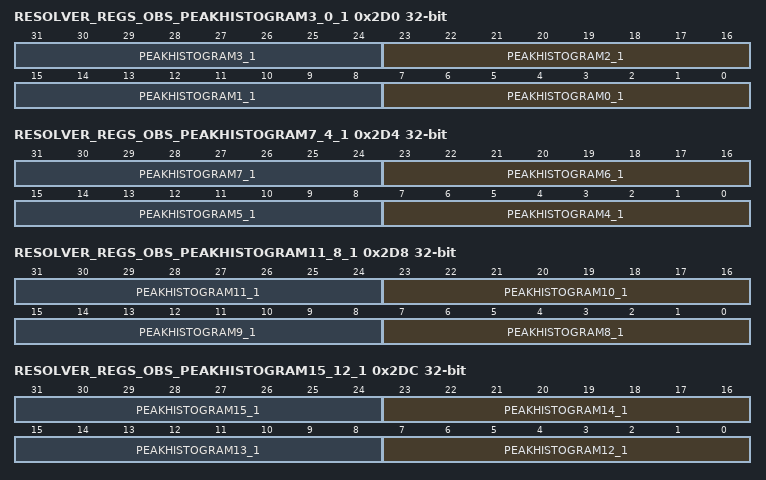
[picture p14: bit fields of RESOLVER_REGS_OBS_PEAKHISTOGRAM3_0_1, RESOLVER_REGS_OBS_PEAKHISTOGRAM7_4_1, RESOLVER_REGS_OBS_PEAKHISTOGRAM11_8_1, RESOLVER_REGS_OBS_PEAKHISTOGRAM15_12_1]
0x2D0 RESOLVER_REGS_OBS_PEAKHISTOGRAM3_0_1 ro — SW obs peak histogram buckets.
  [8n+7:8n] PEAKHISTOGRAM{n}_1 (n=0..3) — Ideal sample bucket{n}
0x2D4 RESOLVER_REGS_OBS_PEAKHISTOGRAM7_4_1 ro — SW obs peak histogram buckets .
  [8n-25:8n-32] PEAKHISTOGRAM{n}_1 (n=4..7) — Ideal sample bucket{n}
0x2D8 RESOLVER_REGS_OBS_PEAKHISTOGRAM11_8_1 ro — SW obs peak histogram buckets .
  [8n-57:8n-64] PEAKHISTOGRAM{n}_1 (n=8..11) — Ideal sample bucket{n}
0x2DC RESOLVER_REGS_OBS_PEAKHISTOGRAM15_12_1 ro — SW obs peak histogram buckets .
  [8n-89:8n-96] PEAKHISTOGRAM{n}_1 (n=12..15) — Ideal sample bucket{n}
0x2E0 RESOLVER_REGS_OBS_PEAKHISTOGRAM19_16_1 ro — SW obs peak histogram buckets .
  [8n-121:8n-128] PEAKHISTOGRAM{n}_1 (n=16..19) — Ideal sample bucket{n}
